# STM32H7R3xx register map
File version: 1.0
Registers are 32-bit, read-write, reset 0x0 unless marked. A register's access mark holds for its fields unless they carry their own. Offsets are from the block's base; [hi:lo] are bit positions; {n}, {i} and the like mark numbered series.

## PWR — Power Control
Base 0x58024800
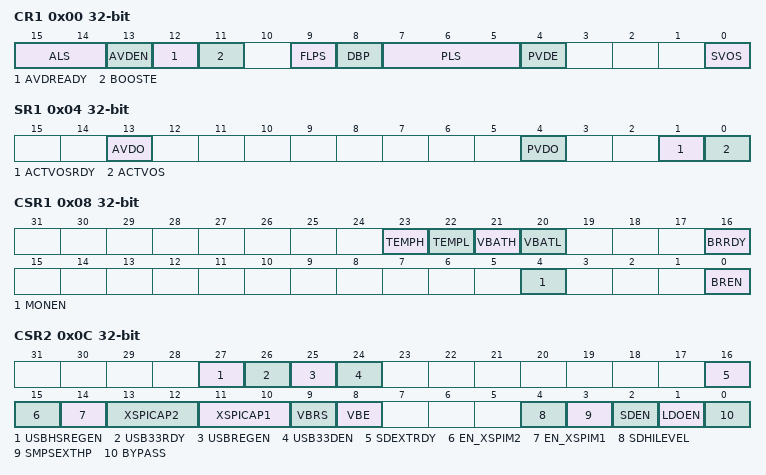
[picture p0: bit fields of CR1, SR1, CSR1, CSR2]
0x00 CR1 — PWR power control register 1
  [15:14] ALS — Analog Voltage Detector level selection
    {v}=AVDLEVEL_{v+1} (Analog Voltage detector level {v+1}) (v=0..3)
  [13] AVDEN — Analog Voltage Detector Enable
  [12] AVDREADY — Analog Voltage Ready
  [11] BOOSTE — Analog Switch VBoost control
  [9] FLPS — Flash low power mode in STOP
  [8] DBP — Disable Back-up domain Protection
  [7:5] PLS — Programmable Voltage Detector level selection
    {v}=PVDLEVEL_{v+1} (v=0..6); 7=EXT
  [4] PVDE — Programmable Voltage detector enable
  [0] SVOS — System STOP mode Voltage Scaling selection
    1=SCALE3 (Voltage scaling range 3 (highest frequency) when system enters STOP mode); 0=SCALE5 (Voltage scaling range 5 (lowest power) when system enters STOP mode)
0x04 SR1 — PWR power status register 1
  [13] AVDO — Analog Voltage Detect Output on VDDA
  [4] PVDO — Programmable Voltage Detect Output
  [1] ACTVOSRDY — Ready bit for current actual used VOS for VDD11 Voltage Scaling
  [0] ACTVOS — VOS currently applied for VCORE voltage scaling selection
0x08 CSR1 — PWR power control status register 1
  [23] TEMPH — Monitored temperature level above high threshold
  [22] TEMPL — Monitored temperature level above low threshold
  [21] VBATH — Monitored VBAT level above high threshold
  [20] VBATL — Monitored VBAT level above low threshold
  [16] BRRDY — Backup regulator ready
  [4] MONEN — VBAT and temperature monitoring enable
  [0] BREN — Backup regulator enable
0x0C CSR2 — PWR power control status register 2
  [27] USBHSREGEN — USB HS regulator enable
  [26] USB33RDY — USB supply ready
  [25] USBREGEN — USB regulator enable
  [24] USB33DEN — VDD33_USB voltage level detector enable
  [16] SDEXTRDY — SMPS External supply ready
  [15] EN_XSPIM2 — XSPIM2 external supply enable
  [14] EN_XSPIM1 — XSPIM1 external supply enable
  [13:12] XSPICAP2 — XSPI port 2 capacitor control bits
    0=OFF (XSPI Port 2 Capacitor OFF); 1=CAPACITOR_1_DIV_3 (XSPI Port 2 Capacitor set to 1/3); 2=CAPACITOR_2_DIV_3 (XSPI Port 2 Capacitor set to 2/3); 3=FULL
  [11:10] XSPICAP1 — XSPI port 1 capacitor control bits
    0=OFF (XSPI Port 1 Capacitor OFF); 1=CAPACITOR_1_DIV_3 (XSPI Port 1 Capacitor set to 1/3); 2=CAPACITOR_2_DIV_3 (XSPI Port 1 Capacitor set to 2/3); 3=FULL
  [9] VBRS — VBAT charging resistor selection
    0=RESISTOR_5K (Charge the Battery through a 5 kO resistor); 1=RESISTOR_1_5K (Charge the Battery through a 1.5 kO resistor)
  [8] VBE — VBAT charging enable
  [4] SDHILEVEL — SMPS step-down converter voltage output for LDO or external supply
  [3] SMPSEXTHP — SMPS external power delivery selection
  [2] SDEN — SMPS Step-down converter enable
  [1] LDOEN — Low Drop-Out regulator enable
  [0] BYPASS — Power Management Unit bypass
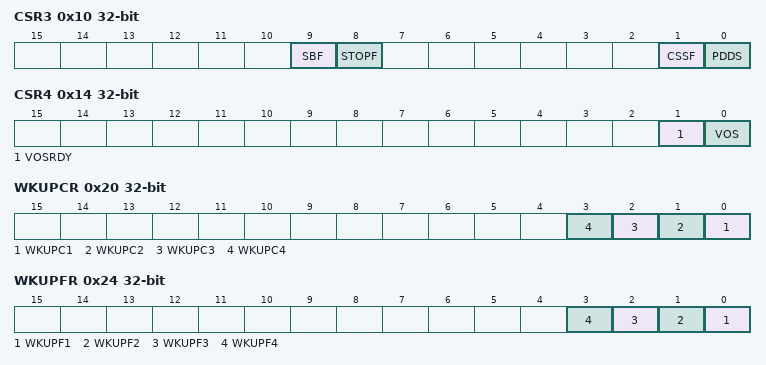
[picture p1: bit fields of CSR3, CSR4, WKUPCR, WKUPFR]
0x10 CSR3 — PWR power control status register 3
  [9] SBF — System STANDBY Flag
  [8] STOPF — STOP Flag
  [1] CSSF — Clear Standby and Stop flag
  [0] PDDS — D1 domain Power Down Deepsleep
    0=STOP (Enter to Stop mode when the CPU enters deepsleep); 1=STANDBY (Enter to Standby mode when the CPU enters deepsleep)
0x14 CSR4 — PWR power control status register 4
  [1] VOSRDY — VOSRDY: VOS Ready bit for VCORE voltage scaling output selection
  [0] VOS — Voltage Scaling selection according performance
    1=SCALE0 (Voltage scaling range 0 (highest frequency)); 0=SCALE1 (Voltage scaling range 1 (lowest power))
0x20 WKUPCR — PWR wakeup clear register
  [n-1] WKUPC{n} (n=1..4) — Clear Wakeup Pin Flag {n}
0x24 WKUPFR — PWR wakeup flag register
  [n-1] WKUPF{n} (n=1..4) — Wakeup Pin Flag {n}
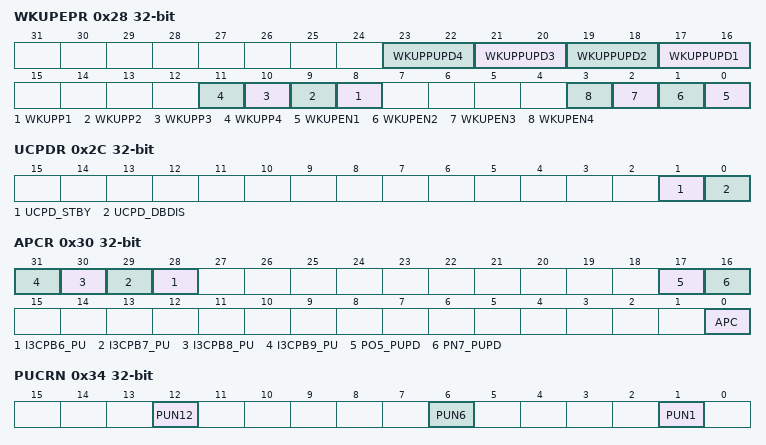
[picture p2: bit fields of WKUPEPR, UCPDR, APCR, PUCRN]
0x28 WKUPEPR — PWR wakeup enable and polarity register
  [2n+15:2n+14] WKUPPUPD{n} (n=1..4) — Wakeup Pin pull configuration for WKUP{n}
  [n+7] WKUPP{n} (n=1..4) — Wakeup Pin Polarity for WKUP{n}
  [n-1] WKUPEN{n} (n=1..4) — Enable Wakeup Pin WKUP{n}
0x2C UCPDR — PWR USB Type-C and power delivery register
  [1] UCPD_STBY — UCPD Standby mode
  [0] UCPD_DBDIS — UCPD dead battery disable
0x30 APCR — PWR apply pull configuration register
  [n+22] I3CPB{n}_PU (n=6..9) — Port PB{n} I3C pull-up bit configuration
  [17] PO5_PUPD — Port O bit 5 pull-up/down configuration
  [16] PN7_PUPD — Port N bit 7 pull-up/down configuration
  [0] APC — Apply pull configuration register
0x34 PUCRN — PWR port N pull-up control register
  [12] PUN12 — PUN12: Port N pull-up
  [6] PUN6 — PUN6: Port N pull-up
  [1] PUN1 — PUN1: Port N pull-up
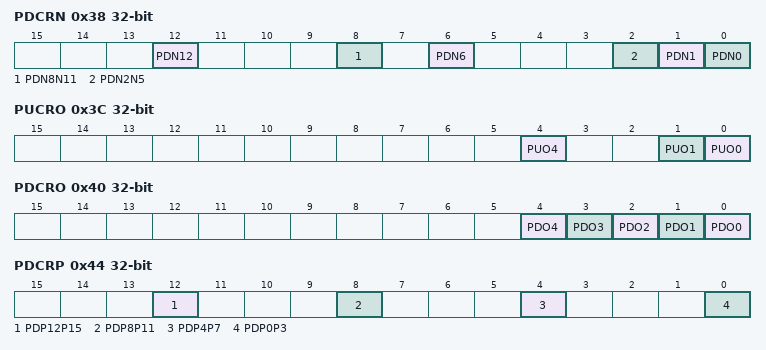
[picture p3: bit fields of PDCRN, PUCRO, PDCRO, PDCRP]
0x38 PDCRN — PWR port N pull-down control register
  [12] PDN12 — PDN12: Port N pull-down
  [8] PDN8N11 — PDN8 to PDN11: Port N pull-down
  [6] PDN6 — PDN6: Port N pull-down
  [2] PDN2N5 — PDN2 to PDN5: Port N pull-down
  [1] PDN1 — PDN1: Port N pull-down
  [0] PDN0 — PDN0: Port N pull-down
0x3C PUCRO — PWR port O pull-up control register
  [4] PUO4 — PUO4: Port O pull-up
  [1] PUO1 — PUO1: Port O pull-up
  [0] PUO0 — PUO0: Port O pull-up
0x40 PDCRO — PWR port O pull-down control register
  [n] PDO{n} (n=0..4) — PDO{n}: Port O pull-down
0x44 PDCRP — PWR port P pull-down control register
  [12] PDP12P15 — PP12 to PP15 : Port P pull-down
  [8] PDP8P11 — PPO8 to PP11 : Port P pull-down
  [4] PDP4P7 — PPO4 to PP07 : Port P pull-down
  [0] PDP0P3 — PPO0 to PP03 : Port P pull-down
0x50 PDR1 — PWR debug register 1
